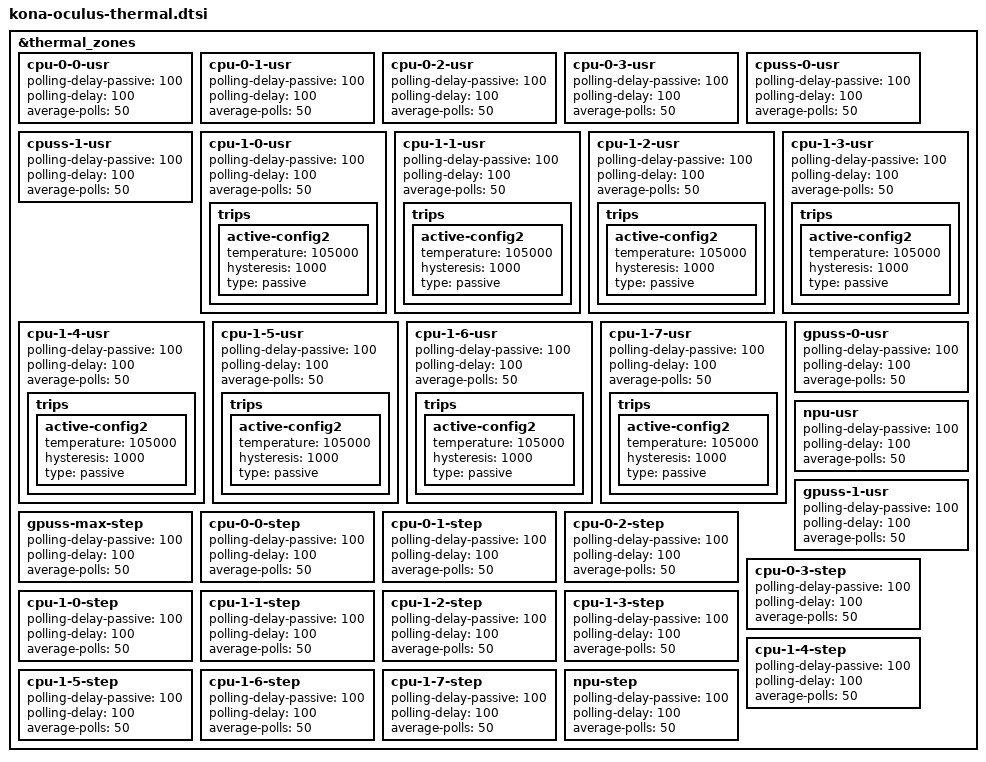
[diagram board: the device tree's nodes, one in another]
// SPDX-License-Identifier: GPL-2.0

&thermal_zones {
	cpu-0-0-usr {
		polling-delay-passive = <100>;
		polling-delay = <100>;
		average-polls = <50>;
	};

	cpu-0-1-usr {
		polling-delay-passive = <100>;
		polling-delay = <100>;
		average-polls = <50>;
	};

	cpu-0-2-usr {
		polling-delay-passive = <100>;
		polling-delay = <100>;
		average-polls = <50>;
	};

	cpu-0-3-usr {
		polling-delay-passive = <100>;
		polling-delay = <100>;
		average-polls = <50>;
	};

	cpuss-0-usr {
		polling-delay-passive = <100>;
		polling-delay = <100>;
		average-polls = <50>;
	};

	cpuss-1-usr {
		polling-delay-passive = <100>;
		polling-delay = <100>;
		average-polls = <50>;
	};

	cpu-1-0-usr {
		polling-delay-passive = <100>;
		polling-delay = <100>;
		average-polls = <50>;
		trips {
			active-config2 {
				temperature = <105000>;
				hysteresis = <1000>;
				type = "passive";
			};
		};
	};

	cpu-1-1-usr {
		polling-delay-passive = <100>;
		polling-delay = <100>;
		average-polls = <50>;
		trips {
			active-config2 {
				temperature = <105000>;
				hysteresis = <1000>;
				type = "passive";
			};
		};
	};

	cpu-1-2-usr {
		polling-delay-passive = <100>;
		polling-delay = <100>;
		average-polls = <50>;
		trips {
			active-config2 {
				temperature = <105000>;
				hysteresis = <1000>;
				type = "passive";
			};
		};
	};

	cpu-1-3-usr {
		polling-delay-passive = <100>;
		polling-delay = <100>;
		average-polls = <50>;
		trips {
			active-config2 {
				temperature = <105000>;
				hysteresis = <1000>;
				type = "passive";
			};
		};
	};

	cpu-1-4-usr {
		polling-delay-passive = <100>;
		polling-delay = <100>;
		average-polls = <50>;
		trips {
			active-config2 {
				temperature = <105000>;
				hysteresis = <1000>;
				type = "passive";
			};
		};
	};

	cpu-1-5-usr {
		polling-delay-passive = <100>;
		polling-delay = <100>;
		average-polls = <50>;
		trips {
			active-config2 {
				temperature = <105000>;
				hysteresis = <1000>;
				type = "passive";
			};
		};
	};

	cpu-1-6-usr {
		polling-delay-passive = <100>;
		polling-delay = <100>;
		average-polls = <50>;
		trips {
			active-config2 {
				temperature = <105000>;
				hysteresis = <1000>;
				type = "passive";
			};
		};
	};

	cpu-1-7-usr {
		polling-delay-passive = <100>;
		polling-delay = <100>;
		average-polls = <50>;
		trips {
			active-config2 {
				temperature = <105000>;
				hysteresis = <1000>;
				type = "passive";
			};
		};
	};

	gpuss-0-usr {
		polling-delay-passive = <100>;
		polling-delay = <100>;
		average-polls = <50>;
	};

	npu-usr {
		polling-delay-passive = <100>;
		polling-delay = <100>;
		average-polls = <50>;
	};

	gpuss-1-usr {
		polling-delay-passive = <100>;
		polling-delay = <100>;
		average-polls = <50>;
	};

	gpuss-max-step {
		polling-delay-passive = <100>;
		polling-delay = <100>;
		average-polls = <50>;
	};

	cpu-0-0-step {
		polling-delay-passive = <100>;
		polling-delay = <100>;
		average-polls = <50>;
	};

	cpu-0-1-step {
		polling-delay-passive = <100>;
		polling-delay = <100>;
		average-polls = <50>;
	};

	cpu-0-2-step {
		polling-delay-passive = <100>;
		polling-delay = <100>;
		average-polls = <50>;
	};

	cpu-0-3-step {
		polling-delay-passive = <100>;
		polling-delay = <100>;
		average-polls = <50>;
	};

	cpu-1-0-step {
		polling-delay-passive = <100>;
		polling-delay = <100>;
		average-polls = <50>;
	};

	cpu-1-1-step {
		polling-delay-passive = <100>;
		polling-delay = <100>;
		average-polls = <50>;
	};

	cpu-1-2-step {
		polling-delay-passive = <100>;
		polling-delay = <100>;
		average-polls = <50>;
	};

	cpu-1-3-step {
		polling-delay-passive = <100>;
		polling-delay = <100>;
		average-polls = <50>;
	};

	cpu-1-4-step {
		polling-delay-passive = <100>;
		polling-delay = <100>;
		average-polls = <50>;
	};

	cpu-1-5-step {
		polling-delay-passive = <100>;
		polling-delay = <100>;
		average-polls = <50>;
	};

	cpu-1-6-step {
		polling-delay-passive = <100>;
		polling-delay = <100>;
		average-polls = <50>;
	};

	cpu-1-7-step {
		polling-delay-passive = <100>;
		polling-delay = <100>;
		average-polls = <50>;
	};

	npu-step {
		polling-delay-passive = <100>;
		polling-delay = <100>;
		average-polls = <50>;
	};
};
